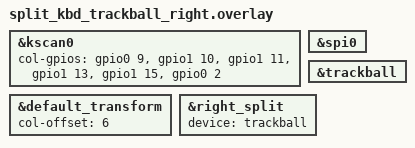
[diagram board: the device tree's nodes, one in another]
#include "split_kbd_trackball.dtsi"
#include "trackball.dtsi"

&kscan0 {
	col-gpios
        = <&gpio0 9 GPIO_ACTIVE_HIGH>
        , <&gpio1 10 GPIO_ACTIVE_HIGH>
        , <&gpio1 11 GPIO_ACTIVE_HIGH>
        , <&gpio1 13 GPIO_ACTIVE_HIGH>
        , <&gpio1 15 GPIO_ACTIVE_HIGH>
        , <&gpio0 2 GPIO_ACTIVE_HIGH>
        ;
};

&default_transform {
	col-offset = <6>;
};

&spi0 {
    status = "okay";
};

&trackball {
    status = "okay";
};

&right_split {
    device = <&trackball>;
};
